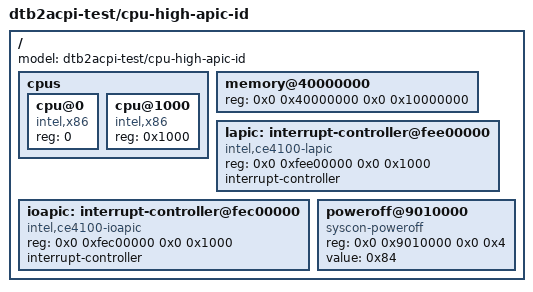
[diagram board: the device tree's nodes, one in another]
/dts-v1/;

/ {
	#address-cells = <2>;
	#size-cells = <2>;
	model = "dtb2acpi-test/cpu-high-apic-id";

	cpus {
		#address-cells = <1>;
		#size-cells = <0>;

		cpu@0 {
			device_type = "cpu";
			reg = <0>;
			compatible = "intel,x86";
		};

		/* APIC ID 4096 forces MADT Type 9 (x2APIC) and SRAT Type 2. */
		cpu@1000 {
			device_type = "cpu";
			reg = <0x1000>;
			compatible = "intel,x86";
		};
	};

	memory@40000000 {
		device_type = "memory";
		reg = <0x0 0x40000000 0x0 0x10000000>;
	};

		lapic: interrupt-controller@fee00000 {
		compatible = "intel,ce4100-lapic";
		reg = <0x0 0xfee00000 0x0 0x1000>;
		interrupt-controller;
		#interrupt-cells = <2>;
	};

	ioapic: interrupt-controller@fec00000 {
		compatible = "intel,ce4100-ioapic";
		reg = <0x0 0xfec00000 0x0 0x1000>;
		interrupt-controller;
		#interrupt-cells = <2>;
	};
		poweroff@9010000 {
		compatible = "syscon-poweroff";
		reg = <0x0 0x9010000 0x0 0x4>;
		value = <0x84>;
	};
};
